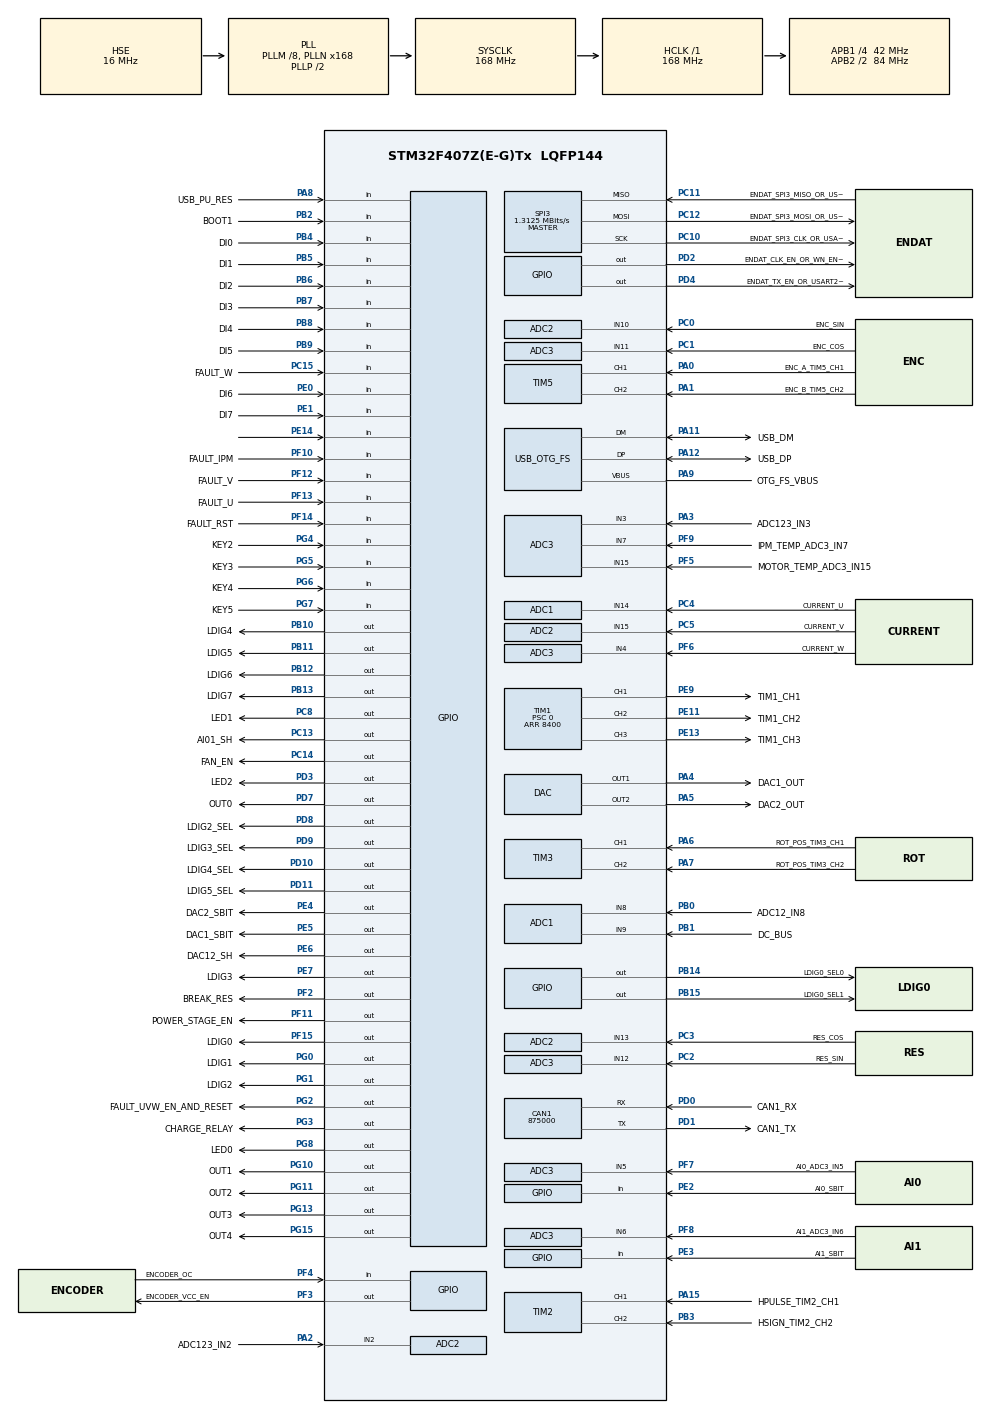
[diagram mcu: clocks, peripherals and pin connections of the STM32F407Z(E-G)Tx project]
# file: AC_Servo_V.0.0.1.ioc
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ADC1.Channel-0\#ChannelRegularConversion=ADC_CHANNEL_8
ADC1.Channel-1\#ChannelInjectedConversion=ADC_CHANNEL_14
ADC1.Channel-2\#ChannelInjectedConversion=ADC_CHANNEL_8
ADC1.Channel-3\#ChannelInjectedConversion=ADC_CHANNEL_9
ADC1.ClockPrescaler=ADC_CLOCK_SYNC_PCLK_DIV4
ADC1.DMAAccessMode=ADC_DMAACCESSMODE_1
ADC1.ExternalTrigInjecConv=ADC_EXTERNALTRIGINJECCONV_T1_TRGO
ADC1.InjNumberOfConversion=3
ADC1.InjectedOffset-1\#ChannelInjectedConversion=0
ADC1.InjectedOffset-2\#ChannelInjectedConversion=0
ADC1.InjectedOffset-3\#ChannelInjectedConversion=0
ADC1.InjectedRank-1\#ChannelInjectedConversion=1
ADC1.InjectedRank-2\#ChannelInjectedConversion=2
ADC1.InjectedRank-3\#ChannelInjectedConversion=3
ADC1.Mode=ADC_TRIPLEMODE_REGSIMULT_INJECSIMULT
ADC1.NbrOfConversionFlag=1
ADC1.Rank-0\#ChannelRegularConversion=1
ADC1.SamplingTime-0\#ChannelRegularConversion=ADC_SAMPLETIME_3CYCLES
ADC1.SamplingTime-1\#ChannelInjectedConversion=ADC_SAMPLETIME_3CYCLES
ADC1.SamplingTime-2\#ChannelInjectedConversion=ADC_SAMPLETIME_3CYCLES
ADC1.SamplingTime-3\#ChannelInjectedConversion=ADC_SAMPLETIME_3CYCLES
ADC1.master=1
ADC2.Channel-0\#ChannelRegularConversion=ADC_CHANNEL_2
ADC2.Channel-1\#ChannelInjectedConversion=ADC_CHANNEL_15
ADC2.Channel-2\#ChannelInjectedConversion=ADC_CHANNEL_2
ADC2.Channel-3\#ChannelInjectedConversion=ADC_CHANNEL_10
ADC2.ClockPrescaler=ADC_CLOCK_SYNC_PCLK_DIV4
ADC2.DMAAccessMode=ADC_DMAACCESSMODE_1
ADC2.InjNumberOfConversion=3
ADC2.InjectedOffset-1\#ChannelInjectedConversion=0
ADC2.InjectedOffset-2\#ChannelInjectedConversion=0
ADC2.InjectedOffset-3\#ChannelInjectedConversion=0
ADC2.InjectedRank-1\#ChannelInjectedConversion=1
ADC2.InjectedRank-2\#ChannelInjectedConversion=2
ADC2.InjectedRank-3\#ChannelInjectedConversion=3
ADC2.Mode=ADC_TRIPLEMODE_REGSIMULT_INJECSIMULT
ADC2.NbrOfConversion=1
ADC2.NbrOfConversionFlag=1
ADC2.Rank-0\#ChannelRegularConversion=1
ADC2.SamplingTime-0\#ChannelRegularConversion=ADC_SAMPLETIME_3CYCLES
ADC2.SamplingTime-1\#ChannelInjectedConversion=ADC_SAMPLETIME_3CYCLES
ADC2.SamplingTime-2\#ChannelInjectedConversion=ADC_SAMPLETIME_3CYCLES
ADC2.SamplingTime-3\#ChannelInjectedConversion=ADC_SAMPLETIME_3CYCLES
ADC3.Channel-0\#ChannelRegularConversion=ADC_CHANNEL_5
ADC3.Channel-1\#ChannelInjectedConversion=ADC_CHANNEL_4
ADC3.Channel-2\#ChannelInjectedConversion=ADC_CHANNEL_3
ADC3.Channel-3\#ChannelInjectedConversion=ADC_CHANNEL_11
ADC3.Channel-4\#ChannelRegularConversion=ADC_CHANNEL_6
ADC3.Channel-5\#ChannelRegularConversion=ADC_CHANNEL_7
ADC3.Channel-6\#ChannelRegularConversion=ADC_CHANNEL_15
ADC3.ClockPrescaler=ADC_CLOCK_SYNC_PCLK_DIV4
ADC3.InjNumberOfConversion=3
ADC3.InjectedOffset-1\#ChannelInjectedConversion=0
ADC3.InjectedOffset-2\#ChannelInjectedConversion=0
ADC3.InjectedOffset-3\#ChannelInjectedConversion=0
ADC3.InjectedRank-1\#ChannelInjectedConversion=1
ADC3.InjectedRank-2\#ChannelInjectedConversion=2
ADC3.InjectedRank-3\#ChannelInjectedConversion=3
ADC3.Mode=ADC_TRIPLEMODE_REGSIMULT_INJECSIMULT
ADC3.NbrOfConversion=4
ADC3.NbrOfConversionFlag=1
ADC3.Rank-0\#ChannelRegularConversion=1
ADC3.Rank-4\#ChannelRegularConversion=2
ADC3.Rank-5\#ChannelRegularConversion=3
ADC3.Rank-6\#ChannelRegularConversion=4
ADC3.SamplingTime-0\#ChannelRegularConversion=ADC_SAMPLETIME_3CYCLES
ADC3.SamplingTime-1\#ChannelInjectedConversion=ADC_SAMPLETIME_3CYCLES
ADC3.SamplingTime-2\#ChannelInjectedConversion=ADC_SAMPLETIME_3CYCLES
ADC3.SamplingTime-3\#ChannelInjectedConversion=ADC_SAMPLETIME_3CYCLES
ADC3.SamplingTime-4\#ChannelRegularConversion=ADC_SAMPLETIME_3CYCLES
ADC3.SamplingTime-5\#ChannelRegularConversion=ADC_SAMPLETIME_3CYCLES
ADC3.SamplingTime-6\#ChannelRegularConversion=ADC_SAMPLETIME_3CYCLES
CAN1.BS1=CAN_BS1_1TQ
CAN1.BS2=CAN_BS2_1TQ
CAN1.CalculateBaudRate=875000
CAN1.CalculateTimeBit=1142
CAN1.CalculateTimeQuantum=380.95238095238096
Dma.ADC3.0.Direction=DMA_PERIPH_TO_MEMORY
Dma.ADC3.0.FIFOMode=DMA_FIFOMODE_DISABLE
Dma.ADC3.0.Instance=DMA2_Stream1
Dma.ADC3.0.MemDataAlignment=DMA_MDATAALIGN_HALFWORD
Dma.ADC3.0.MemInc=DMA_MINC_ENABLE
Dma.ADC3.0.Mode=DMA_CIRCULAR
Dma.ADC3.0.PeriphDataAlignment=DMA_PDATAALIGN_HALFWORD
Dma.ADC3.0.PeriphInc=DMA_PINC_DISABLE
Dma.ADC3.0.Priority=DMA_PRIORITY_LOW
Dma.Request0=ADC3
Mcu.Family=STM32F4
Mcu.Name=STM32F407Z(E-G)Tx
Mcu.Package=LQFP144
NVIC.ADC_IRQn=true\:0\:0\:false\:false\:true\:true\:false\:true
NVIC.DMA2_Stream1_IRQn=true\:0\:0\:false\:false\:true\:false\:false\:true
NVIC.OTG_FS_IRQn=true\:0\:0\:false\:false\:true\:false\:true\:true
NVIC.PriorityGroup=NVIC_PRIORITYGROUP_4
NVIC.TIM1_BRK_TIM9_IRQn=true\:0\:0\:false\:false\:true\:true\:false\:true
PA0-WKUP.GPIO_Label=ENC_A_TIM5_CH1
PA0-WKUP.Signal=S_TIM5_CH1
PA1.GPIO_Label=ENC_B_TIM5_CH2
PA1.Signal=S_TIM5_CH2
PA10.GPIO_Label=USB_ID
PA10.Signal=USB_OTG_FS_ID
PA11.GPIO_Label=USB_DM
PA11.Mode=Device_Only
PA11.Signal=USB_OTG_FS_DM
PA12.GPIO_Label=USB_DP
PA12.Mode=Device_Only
PA12.Signal=USB_OTG_FS_DP
PA13.GPIO_Label=SWDIO
PA13.Signal=SYS_JTMS-SWDIO
PA14.GPIO_Label=SWCLK
PA14.Signal=SYS_JTCK-SWCLK
PA15.GPIO_Label=HPULSE_TIM2_CH1
PA15.Signal=S_TIM2_CH1_ETR
PA2.GPIO_Label=ADC123_IN2
PA2.Signal=ADCx_IN2
PA3.GPIO_Label=ADC123_IN3
PA3.Signal=ADCx_IN3
PA4.GPIO_Label=DAC1_OUT
PA4.Signal=COMP_DAC1_group
PA5.GPIO_Label=DAC2_OUT
PA5.Signal=COMP_DAC2_group
PA6.GPIO_Label=ROT_POS_TIM3_CH1
PA6.Signal=S_TIM3_CH1
PA7.GPIO_Label=ROT_POS_TIM3_CH2
PA7.Signal=S_TIM3_CH2
PA8.GPIO_Label=USB_PU_RES
PA8.Signal=GPIO_Input
PA9.GPIO_Label=OTG_FS_VBUS
PA9.Mode=Activate_VBUS
PA9.Signal=USB_OTG_FS_VBUS
PB0.GPIO_Label=ADC12_IN8
PB0.Signal=ADCx_IN8
PB1.GPIO_Label=DC_BUS
PB1.Signal=ADCx_IN9
PB10.GPIO_Label=LDIG4
PB10.Signal=GPIO_Output
PB11.GPIO_Label=LDIG5
PB11.Signal=GPIO_Output
PB12.GPIO_Label=LDIG6
PB12.GPIO_Speed=GPIO_SPEED_FREQ_LOW
PB12.Signal=GPIO_Output
PB13.GPIO_Label=LDIG7
PB13.Signal=GPIO_Output
PB14.GPIO_Label=LDIG0_SEL0
PB14.Signal=GPIO_Output
PB15.GPIO_Label=LDIG0_SEL1
PB15.Signal=GPIO_Output
PB2.GPIO_Label=BOOT1
PB2.Signal=GPIO_Input
PB3.GPIO_Label=HSIGN_TIM2_CH2
PB3.Signal=S_TIM2_CH2
PB4.GPIO_Label=DI0
PB4.Signal=GPIO_Input
PB5.GPIO_Label=DI1
PB5.Signal=GPIO_Input
PB6.GPIO_Label=DI2
PB6.Signal=GPIO_Input
PB7.GPIO_Label=DI3
PB7.Signal=GPIO_Input
PB8.GPIO_Label=DI4
PB8.Signal=GPIO_Input
PB9.GPIO_Label=DI5
PB9.Signal=GPIO_Input
PC0.GPIO_Label=ENC_SIN
PC0.Signal=ADCx_IN10
PC1.GPIO_Label=ENC_COS
PC1.Signal=ADCx_IN11
PC10.GPIO_Label=ENDAT_SPI3_CLK_OR_USART3_TX
PC10.Mode=Full_Duplex_Master
PC10.Signal=SPI3_SCK
PC11.GPIO_Label=ENDAT_SPI3_MISO_OR_USART3_RX
PC11.GPIO_PuPd=GPIO_NOPULL
PC11.Mode=Full_Duplex_Master
PC11.Signal=SPI3_MISO
PC12.GPIO_Label=ENDAT_SPI3_MOSI_OR_USART3_CK
PC12.GPIO_PuPd=GPIO_NOPULL
PC12.Mode=Full_Duplex_Master
PC12.Signal=SPI3_MOSI
PC13-ANTI_TAMP.GPIO_Label=AI01_SH
PC13-ANTI_TAMP.Signal=GPIO_Output
PC14-OSC32_IN.GPIO_Label=FAN_EN
PC14-OSC32_IN.Signal=GPIO_Output
PC15-OSC32_OUT.GPIO_Label=FAULT_W
PC15-OSC32_OUT.Signal=GPIO_Input
PC2.GPIO_Label=RES_SIN
PC2.Signal=ADCx_IN12
PC3.GPIO_Label=RES_COS
PC3.Signal=ADCx_IN13
PC4.GPIO_Label=CURRENT_U
PC4.Signal=ADCx_IN14
PC5.GPIO_Label=CURRENT_V
PC5.Signal=ADCx_IN15
PC6.GPIO_Label=PULSE_TIM8_CH1
PC6.Signal=S_TIM8_CH1
PC7.GPIO_Label=SIGN_TIM8_CH2
PC7.Signal=S_TIM8_CH2
PC8.GPIO_Label=LED1
PC8.Signal=GPIO_Output
PC9.GPIO_Label=ENC_Z
PC9.Signal=S_TIM3_CH4
PD0.GPIO_Label=CAN1_RX
PD0.Mode=CAN_Activate
PD0.Signal=CAN1_RX
PD1.GPIO_Label=CAN1_TX
PD1.Mode=CAN_Activate
PD1.Signal=CAN1_TX
PD10.GPIO_Label=LDIG4_SEL
PD10.Signal=GPIO_Output
PD11.GPIO_Label=LDIG5_SEL
PD11.Signal=GPIO_Output
PD12.GPIO_Label=TIM4_CH1
PD12.Signal=S_TIM4_CH1
PD13.GPIO_Label=ENC_U
PD13.Signal=S_TIM4_CH2
PD14.GPIO_Label=ENC_V
PD14.Signal=S_TIM4_CH3
PD15.GPIO_Label=ENC_W
PD15.Signal=S_TIM4_CH4
PD2.GPIO_Label=ENDAT_CLK_EN_OR_WN_ENABLE
PD2.Signal=GPIO_Output
PD3.GPIO_Label=LED2
PD3.Signal=GPIO_Output
PD4.GPIO_Label=ENDAT_TX_EN_OR_USART2_RTS
PD4.Signal=GPIO_Output
PD5.GPIO_Label=USART2_TX
PD5.Signal=USART2_TX
PD6.GPIO_Label=USART2_RX
PD6.Signal=USART2_RX
PD7.GPIO_Label=OUT0
PD7.Signal=GPIO_Output
PD8.GPIO_Label=LDIG2_SEL
PD8.Signal=GPIO_Output
PD9.GPIO_Label=LDIG3_SEL
PD9.Signal=GPIO_Output
PE0.GPIO_Label=DI6
PE0.Signal=GPIO_Input
PE1.GPIO_Label=DI7
PE1.Signal=GPIO_Input
PE10.GPIO_Label=TIM1_CH2N
PE10.Signal=TIM1_CH2N
PE11.GPIO_Label=TIM1_CH2
PE11.Signal=S_TIM1_CH2
PE12.GPIO_Label=TIM1_CH3N
PE12.Signal=TIM1_CH3N
PE13.GPIO_Label=TIM1_CH3
PE13.Signal=S_TIM1_CH3
PE14.Signal=GPIO_Input
PE15.GPIO_Label=FAULT_PWM_DISABLE_TIM1_BKIN
PE15.Signal=TIM1_BKIN
PE2.GPIO_Label=AI0_SBIT
PE2.Signal=GPIO_Input
PE3.GPIO_Label=AI1_SBIT
PE3.Signal=GPIO_Input
PE4.GPIO_Label=DAC2_SBIT
PE4.Signal=GPIO_Output
PE5.GPIO_Label=DAC1_SBIT
PE5.Signal=GPIO_Output
PE6.GPIO_Label=DAC12_SH
PE6.Signal=GPIO_Output
PE7.GPIO_Label=LDIG3
PE7.Signal=GPIO_Output
PE8.GPIO_Label=TIM1_CH1N
PE8.Signal=TIM1_CH1N
PE9.GPIO_Label=TIM1_CH1
PE9.Signal=S_TIM1_CH1
PF0.GPIO_Label=I2C2_SDA
PF0.Signal=I2C2_SDA
PF1.GPIO_Label=I2C2_SCL
PF1.Signal=I2C2_SCL
PF10.GPIO_Label=FAULT_IPM
PF10.Signal=GPIO_Input
PF11.GPIO_Label=POWER_STAGE_EN
PF11.Signal=GPIO_Output
PF12.GPIO_Label=FAULT_V
PF12.Signal=GPIO_Input
PF13.GPIO_Label=FAULT_U
PF13.Signal=GPIO_Input
PF14.GPIO_Label=FAULT_RST
PF14.Signal=GPIO_Input
PF15.GPIO_Label=LDIG0
PF15.Signal=GPIO_Output
PF2.GPIO_Label=BREAK_RES
PF2.Signal=GPIO_Output
PF3.GPIO_Label=ENCODER_VCC_EN
PF3.GPIO_ModeDefaultOutputPP=GPIO_MODE_OUTPUT_OD
PF3.PinState=GPIO_PIN_SET
PF3.Signal=GPIO_Output
PF4.GPIO_Label=ENCODER_OC
PF4.Signal=GPIO_Input
PF5.GPIO_Label=MOTOR_TEMP_ADC3_IN15
PF5.Mode=IN15
PF5.Signal=ADC3_IN15
PF6.GPIO_Label=CURRENT_W
PF6.Mode=IN4
PF6.Signal=ADC3_IN4
PF7.GPIO_Label=AI0_ADC3_IN5
PF7.Mode=IN5
PF7.Signal=ADC3_IN5
PF8.GPIO_Label=AI1_ADC3_IN6
PF8.Mode=IN6
PF8.Signal=ADC3_IN6
PF9.GPIO_Label=IPM_TEMP_ADC3_IN7
PF9.Mode=IN7
PF9.Signal=ADC3_IN7
PG0.GPIO_Label=LDIG1
PG0.Signal=GPIO_Output
PG1.GPIO_Label=LDIG2
PG1.Signal=GPIO_Output
PG10.GPIO_Label=OUT1
PG10.Signal=GPIO_Output
PG11.GPIO_Label=OUT2
PG11.Signal=GPIO_Output
PG12.GPIO_Label=RS485_DE_USART6_RTS
PG12.Signal=USART6_RTS
PG13.GPIO_Label=OUT3
PG13.Signal=GPIO_Output
PG14.GPIO_Label=RS485_TX_USART6_TX
PG14.Signal=USART6_TX
PG15.GPIO_Label=OUT4
PG15.Signal=GPIO_Output
PG2.GPIO_Label=FAULT_UVW_EN_AND_RESET
PG2.Signal=GPIO_Output
PG3.GPIO_Label=CHARGE_RELAY
PG3.Signal=GPIO_Output
PG4.GPIO_Label=KEY2
PG4.Signal=GPIO_Input
PG5.GPIO_Label=KEY3
PG5.Signal=GPIO_Input
PG6.GPIO_Label=KEY4
PG6.Signal=GPIO_Input
PG7.GPIO_Label=KEY5
PG7.Signal=GPIO_Input
PG8.GPIO_Label=LED0
PG8.Signal=GPIO_Output
PG9.GPIO_Label=RS485_RX_USART6_RX
PG9.Signal=USART6_RX
PH0-OSC_IN.Mode=HSE-External-Oscillator
PH0-OSC_IN.Signal=RCC_OSC_IN
PH1-OSC_OUT.Mode=HSE-External-Oscillator
PH1-OSC_OUT.Signal=RCC_OSC_OUT
ProjectManager.HeapSize=0x200
ProjectManager.StackSize=0x400
ProjectManager.TargetToolchain=STM32CubeIDE
RCC.48MHZClocksFreq_Value=48000000
RCC.AHBFreq_Value=168000000
RCC.APB1CLKDivider=RCC_HCLK_DIV4
RCC.APB1Freq_Value=42000000
RCC.APB1TimFreq_Value=84000000
RCC.APB2CLKDivider=RCC_HCLK_DIV2
RCC.APB2Freq_Value=84000000
RCC.APB2TimFreq_Value=168000000
RCC.CortexFreq_Value=168000000
RCC.HCLKFreq_Value=168000000
RCC.HSE_VALUE=16000000
RCC.HSI_VALUE=16000000
RCC.LSE_VALUE=32768
RCC.PLLM=8
RCC.PLLN=168
RCC.PLLQ=7
RCC.SYSCLKFreq_VALUE=168000000
RCC.SYSCLKSource=RCC_SYSCLKSOURCE_PLLCLK
RCC.VCOOutputFreq_Value=336000000
SH.ADCx_IN10.0=ADC2_IN10,IN10
SH.ADCx_IN11.0=ADC3_IN11,IN11
SH.ADCx_IN12.0=ADC3_IN12,IN12
SH.ADCx_IN13.0=ADC2_IN13,IN13
SH.ADCx_IN14.0=ADC1_IN14,IN14
SH.ADCx_IN15.0=ADC2_IN15,IN15
SH.ADCx_IN2.0=ADC2_IN2,IN2
SH.ADCx_IN3.0=ADC3_IN3,IN3
SH.ADCx_IN8.0=ADC1_IN8,IN8
SH.ADCx_IN9.0=ADC1_IN9,IN9
SH.COMP_DAC1_group.0=DAC_OUT1,DAC_OUT1
SH.COMP_DAC2_group.0=DAC_OUT2,DAC_OUT2
SH.S_TIM1_CH1.0=TIM1_CH1,PWM Generation1 CH1
SH.S_TIM1_CH2.0=TIM1_CH2,PWM Generation2 CH2
SH.S_TIM1_CH3.0=TIM1_CH3,PWM Generation3 CH3
SH.S_TIM2_CH1_ETR.0=TIM2_CH1,Encoder_Interface
SH.S_TIM2_CH2.0=TIM2_CH2,Encoder_Interface
SH.S_TIM3_CH1.0=TIM3_CH1,Encoder_Interface
SH.S_TIM3_CH2.0=TIM3_CH2,Encoder_Interface
SH.S_TIM3_CH4.0=TIM3_CH4
SH.S_TIM4_CH1.0=TIM4_CH1
SH.S_TIM4_CH2.0=TIM4_CH2
SH.S_TIM4_CH3.0=TIM4_CH3
SH.S_TIM4_CH4.0=TIM4_CH4
SH.S_TIM5_CH1.0=TIM5_CH1,Encoder_Interface
SH.S_TIM5_CH2.0=TIM5_CH2,Encoder_Interface
SH.S_TIM8_CH1.0=TIM8_CH1
SH.S_TIM8_CH2.0=TIM8_CH2
SPI3.BaudRatePrescaler=SPI_BAUDRATEPRESCALER_32
SPI3.CLKPolarity=SPI_POLARITY_HIGH
SPI3.CalculateBaudRate=1.3125 MBits/s
SPI3.Direction=SPI_DIRECTION_2LINES
SPI3.FirstBit=SPI_FIRSTBIT_LSB
SPI3.Mode=SPI_MODE_MASTER
SPI3.VirtualType=VM_MASTER
TIM1.AutoReloadPreload=TIM_AUTORELOAD_PRELOAD_ENABLE
TIM1.AutomaticOutput=TIM_AUTOMATICOUTPUT_DISABLE
TIM1.BreakPolarity=TIM_BREAKPOLARITY_LOW
TIM1.BreakState=TIM_BREAK_ENABLE
TIM1.Channel-PWM\ Generation1\ CH1=TIM_CHANNEL_1
TIM1.Channel-PWM\ Generation2\ CH2=TIM_CHANNEL_2
TIM1.Channel-PWM\ Generation3\ CH3=TIM_CHANNEL_3
TIM1.Channel-PWM\ Generation4\ No\ Output=TIM_CHANNEL_4
TIM1.CounterMode=TIM_COUNTERMODE_CENTERALIGNED1
TIM1.OCMode_PWM-PWM\ Generation1\ CH1=TIM_OCMODE_PWM1
TIM1.OCMode_PWM-PWM\ Generation2\ CH2=TIM_OCMODE_PWM1
TIM1.OCMode_PWM-PWM\ Generation3\ CH3=TIM_OCMODE_PWM1
TIM1.OffStateIDLEMode=TIM_OSSI_ENABLE
TIM1.OffStateRunMode=TIM_OSSR_ENABLE
TIM1.Period=8400
TIM1.Prescaler=0
TIM1.Pulse-PWM\ Generation1\ CH1=4200
TIM1.Pulse-PWM\ Generation2\ CH2=4200
TIM1.Pulse-PWM\ Generation3\ CH3=4200
TIM1.Pulse-PWM\ Generation4\ No\ Output=100
TIM1.RepetitionCounter=1
TIM1.TIM_MasterOutputTrigger=TIM_TRGO_UPDATE
TIM2.IC1Filter=15
TIM2.IC2Filter=15
TIM3.IC1Filter=15
TIM3.IC2Filter=15
USB_DEVICE.CLASS_NAME_FS=CDC
USB_DEVICE.VirtualMode-CDC_FS=Cdc
USB_DEVICE.VirtualModeFS=Cdc_FS
USB_OTG_FS.VirtualMode=Device_Only
VP_TIM1_VS_ClockSourceINT.Mode=Internal
VP_TIM1_VS_no_output4.Mode=PWM Generation4 No Output
VP_USB_DEVICE_VS_USB_DEVICE_CDC_FS.Mode=CDC_FS
board=custom

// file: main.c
/* USER CODE BEGIN Header */
/**
  ******************************************************************************
  * @file           : main.c
  * @brief          : Main program body
  ******************************************************************************
  * @attention
  *
  * <h2><center>&copy; Copyright (c) 2019 STMicroelectronics.
  * All rights reserved.</center></h2>
  *
  * This software component is licensed by ST under BSD 3-Clause license,
  * the "License"; You may not use this file except in compliance with the
  * License. You may obtain a copy of the License at:
  *                        opensource.org/licenses/BSD-3-Clause
  *
  ******************************************************************************
  */
/* USER CODE END Header */
#include "main.h"

/* USER CODE BEGIN Includes */
#include <math.h>
#include "endat.h"
#include "foc.h"
/* USER CODE END Includes */

ADC_HandleTypeDef hadc1;
ADC_HandleTypeDef hadc2;
ADC_HandleTypeDef hadc3;
DMA_HandleTypeDef hdma_adc3;

CAN_HandleTypeDef hcan1;

DAC_HandleTypeDef hdac;

SPI_HandleTypeDef hspi3;

TIM_HandleTypeDef htim1;
TIM_HandleTypeDef htim2;
TIM_HandleTypeDef htim3;
TIM_HandleTypeDef htim5;

PCD_HandleTypeDef hpcd_USB_OTG_FS;

/* USER CODE BEGIN PV */
volatile uint8_t encoder_pwr_en = 1;
volatile uint16_t arrADC[15];
volatile float s, c;

volatile int16_t arrADC1[15];
volatile uint16_t arrOffset[15];
volatile uint32_t arrOffsetSum[15];

volatile float angle, delta = 0.0f;
volatile float min = 0, max = 0, angle;

volatile uint16_t tim3;
volatile uint32_t tim5, upos;
volatile int32_t pos;

endat_data_t st_EnDat;

uint8_t main_state = 0;

uint8_t adc_is_ready = 0;
uint32_t sin_sum, cos_sum, average_cnt;

MC_FOC stFoc;
/* USER CODE END PV */

void SystemClock_Config(void);
static void MX_GPIO_Init(void);
static void MX_DMA_Init(void);
static void MX_TIM1_Init(void);
static void MX_TIM2_Init(void);
static void MX_TIM3_Init(void);
static void MX_TIM5_Init(void);
static void MX_ADC1_Init(void);
static void MX_ADC2_Init(void);
static void MX_ADC3_Init(void);
static void MX_DAC_Init(void);
static void MX_SPI3_Init(void);
static void MX_CAN1_Init(void);
static void MX_USB_OTG_FS_PCD_Init(void);

int main(void)
{

  /* MCU Configuration--------------------------------------------------------*/

  /* Reset of all peripherals, Initializes the Flash interface and the Systick. */
  HAL_Init();

  /* Configure the system clock */
  SystemClock_Config();

  /* USER CODE BEGIN SysInit */
  focInit( &stFoc );
  createSinCosTable();
  /* USER CODE END SysInit */

  /* Initialize all configured peripherals */
  MX_GPIO_Init();
  MX_DMA_Init();
  MX_TIM1_Init();
  MX_TIM2_Init();
  MX_TIM3_Init();
  MX_TIM5_Init();
  MX_ADC1_Init();
  MX_ADC2_Init();
  MX_ADC3_Init();
  MX_DAC_Init();
  MX_SPI3_Init();
  MX_CAN1_Init();
  MX_USB_OTG_FS_PCD_Init();
  /* USER CODE BEGIN 2 */
  HAL_TIM_PWM_Start( &htim1, TIM_CHANNEL_1 );
  HAL_TIM_PWM_Start( &htim1, TIM_CHANNEL_2 );
  HAL_TIM_PWM_Start( &htim1, TIM_CHANNEL_3 );
  HAL_TIM_PWM_Start( &htim1, TIM_CHANNEL_4 );
  /* USER CODE END 2 */

  /* Infinite loop */
  /* USER CODE BEGIN WHILE */
//en_dat_inti();
  HAL_GPIO_WritePin( GPIOD, ENDAT_CLK_EN_OR_WN_ENABLE_Pin, GPIO_PIN_SET );
  while (1)
  {
	  switch( main_state )
	  {
	  case 0:
		  stFoc.enable = 0;

		  encoder_pwr_en = 0;;
		  sin_sum = 0;
		  cos_sum = 0;
		  average_cnt = 0;
		  main_state = 1;
		  break;

	  case 1:
		  if( average_cnt < 1000 )
		  {
			  average_cnt++;
		  } else {
			  average_cnt = 0;
			  main_state = 2;
		  }
		  break;

	  case 2:
		  if( average_cnt < 8 )
		  {
			  if( adc_is_ready )
			  {
				  average_cnt++;

				  for( int i = 0; i < 15; i++ )
				  {
					  arrOffsetSum[i] += arrADC[i];
				  }

				  adc_is_ready = 0;
			  }
		  } else {
			  for( int i = 0; i < 15; i++ )
			  {
				  arrOffset[i] = arrOffsetSum[i] / 8;
			  }

			  stFoc.current_a_offset = arrOffset[0];
			  stFoc.current_b_offset = arrOffset[4];
			  stFoc.current_c_offset = arrOffset[8];
			  main_state = 3;
		  }
		  break;

	  case 3:
		  encoder_pwr_en = 1;
		  main_state = 4;
		  break;

	  case 4:
		  stFoc.enable = 1;

		  for( int i = 0; i < 15; i++ )
		  {
			  arrADC1[i] = arrADC[i] - arrOffset[i];
		  }

		  if( arrADC1[10] )
		  {
			  int32_t temp;
			  float at;

			  s = arrADC1[6];
			  c = arrADC1[10];
			  at = 4095.0f - ( 4095.0f * (( 1.5232 + atan( s / c ) ) / 3.09324f) );

			  //temp = ( ( tim5 % 1023 ) << 12) + ( (uint16_t)at & 0x0fff );
			  temp = ( tim3<<12) + ( (uint16_t)at & 0x0fff );
			  angle= (float)temp / 4096.0f;
			  pos = temp;
		  }

		  //GPIOD->BSRR |= LED2_Pin;
		  endat_func( 0.0f, &st_EnDat );
		  //GPIOD->BSRR |= LED2_Pin<<16;
		  break;
	  }

	  if( encoder_pwr_en )
	  {
		  HAL_GPIO_WritePin(ENCODER_VCC_EN_GPIO_Port, ENCODER_VCC_EN_Pin, GPIO_PIN_RESET);
	  } else {
		  HAL_GPIO_WritePin(ENCODER_VCC_EN_GPIO_Port, ENCODER_VCC_EN_Pin, GPIO_PIN_SET);
	  }

	  HAL_DAC_SetValue( &hdac, DAC_CHANNEL_1, DAC_ALIGN_12B_R, angle+1500 );
	  HAL_DAC_SetValue( &hdac, DAC_CHANNEL_2, DAC_ALIGN_12B_R, 0 );

    /* USER CODE END WHILE */

    /* USER CODE BEGIN 3 */
	  /*uint8_t txEnData[10];

	  txEnData[0] = 0xAA;
	  txEnData[1] = 0x55;

	  HAL_GPIO_WritePin( GPIOD, ENDAT_TX_EN_OR_USART2_RTS_Pin, GPIO_PIN_SET );
	  HAL_SPI_Transmit( &hspi3, txEnData, 10, 1 );
	  HAL_GPIO_WritePin( GPIOD, ENDAT_TX_EN_OR_USART2_RTS_Pin, GPIO_PIN_RESET );*/
  }
  /* USER CODE END 3 */
}

void SystemClock_Config(void)
{
  RCC_OscInitTypeDef RCC_OscInitStruct = {0};
  RCC_ClkInitTypeDef RCC_ClkInitStruct = {0};

  /** Configure the main internal regulator output voltage
  */
  __HAL_RCC_PWR_CLK_ENABLE();
  __HAL_PWR_VOLTAGESCALING_CONFIG(PWR_REGULATOR_VOLTAGE_SCALE1);
  /** Initializes the RCC Oscillators according to the specified parameters
  * in the RCC_OscInitTypeDef structure.
  */
  RCC_OscInitStruct.OscillatorType = RCC_OSCILLATORTYPE_HSE;
  RCC_OscInitStruct.HSEState = RCC_HSE_ON;
  RCC_OscInitStruct.PLL.PLLState = RCC_PLL_ON;
  RCC_OscInitStruct.PLL.PLLSource = RCC_PLLSOURCE_HSE;
  RCC_OscInitStruct.PLL.PLLM = 8;
  RCC_OscInitStruct.PLL.PLLN = 168;
  RCC_OscInitStruct.PLL.PLLP = RCC_PLLP_DIV2;
  RCC_OscInitStruct.PLL.PLLQ = 7;
  if (HAL_RCC_OscConfig(&RCC_OscInitStruct) != HAL_OK)
  {
    Error_Handler();
  }
  /** Initializes the CPU, AHB and APB buses clocks
  */
  RCC_ClkInitStruct.ClockType = RCC_CLOCKTYPE_HCLK|RCC_CLOCKTYPE_SYSCLK
                              |RCC_CLOCKTYPE_PCLK1|RCC_CLOCKTYPE_PCLK2;
  RCC_ClkInitStruct.SYSCLKSource = RCC_SYSCLKSOURCE_PLLCLK;
  RCC_ClkInitStruct.AHBCLKDivider = RCC_SYSCLK_DIV1;
  RCC_ClkInitStruct.APB1CLKDivider = RCC_HCLK_DIV4;
  RCC_ClkInitStruct.APB2CLKDivider = RCC_HCLK_DIV2;

  if (HAL_RCC_ClockConfig(&RCC_ClkInitStruct, FLASH_LATENCY_5) != HAL_OK)
  {
    Error_Handler();
  }
}

static void MX_ADC1_Init(void)
{

  ADC_MultiModeTypeDef multimode = {0};
  ADC_ChannelConfTypeDef sConfig = {0};
  ADC_InjectionConfTypeDef sConfigInjected = {0};

  /** Configure the global features of the ADC (Clock, Resolution, Data Alignment and number of conversion)
  */
  hadc1.Instance = ADC1;
  hadc1.Init.ClockPrescaler = ADC_CLOCK_SYNC_PCLK_DIV4;
  hadc1.Init.Resolution = ADC_RESOLUTION_12B;
  hadc1.Init.ScanConvMode = ENABLE;
  hadc1.Init.ContinuousConvMode = DISABLE;
  hadc1.Init.DiscontinuousConvMode = DISABLE;
  hadc1.Init.ExternalTrigConvEdge = ADC_EXTERNALTRIGCONVEDGE_NONE;
  hadc1.Init.ExternalTrigConv = ADC_SOFTWARE_START;
  hadc1.Init.DataAlign = ADC_DATAALIGN_RIGHT;
  hadc1.Init.NbrOfConversion = 1;
  hadc1.Init.DMAContinuousRequests = DISABLE;
  hadc1.Init.EOCSelection = ADC_EOC_SINGLE_CONV;
  if (HAL_ADC_Init(&hadc1) != HAL_OK)
  {
    Error_Handler();
  }
  /** Configure the ADC multi-mode
  */
  multimode.Mode = ADC_TRIPLEMODE_REGSIMULT_INJECSIMULT;
  multimode.DMAAccessMode = ADC_DMAACCESSMODE_1;
  multimode.TwoSamplingDelay = ADC_TWOSAMPLINGDELAY_5CYCLES;
  if (HAL_ADCEx_MultiModeConfigChannel(&hadc1, &multimode) != HAL_OK)
  {
    Error_Handler();
  }
  /** Configure for the selected ADC regular channel its corresponding rank in the sequencer and its sample time.
  */
  sConfig.Channel = ADC_CHANNEL_8;
  sConfig.Rank = 1;
  sConfig.SamplingTime = ADC_SAMPLETIME_3CYCLES;
  if (HAL_ADC_ConfigChannel(&hadc1, &sConfig) != HAL_OK)
  {
    Error_Handler();
  }
  /** Configures for the selected ADC injected channel its corresponding rank in the sequencer and its sample time
  */
  sConfigInjected.InjectedChannel = ADC_CHANNEL_14;
  sConfigInjected.InjectedRank = 1;
  sConfigInjected.InjectedNbrOfConversion = 3;
  sConfigInjected.InjectedSamplingTime = ADC_SAMPLETIME_3CYCLES;
  sConfigInjected.ExternalTrigInjecConvEdge = ADC_EXTERNALTRIGINJECCONVEDGE_RISING;
  sConfigInjected.ExternalTrigInjecConv = ADC_EXTERNALTRIGINJECCONV_T1_TRGO;
  sConfigInjected.AutoInjectedConv = DISABLE;
  sConfigInjected.InjectedDiscontinuousConvMode = DISABLE;
  sConfigInjected.InjectedOffset = 0;
  if (HAL_ADCEx_InjectedConfigChannel(&hadc1, &sConfigInjected) != HAL_OK)
  {
    Error_Handler();
  }
  /** Configures for the selected ADC injected channel its corresponding rank in the sequencer and its sample time
  */
  sConfigInjected.InjectedChannel = ADC_CHANNEL_8;
  sConfigInjected.InjectedRank = 2;
  if (HAL_ADCEx_InjectedConfigChannel(&hadc1, &sConfigInjected) != HAL_OK)
  {
    Error_Handler();
  }
  /** Configures for the selected ADC injected channel its corresponding rank in the sequencer and its sample time
  */
  sConfigInjected.InjectedChannel = ADC_CHANNEL_9;
  sConfigInjected.InjectedRank = 3;
  if (HAL_ADCEx_InjectedConfigChannel(&hadc1, &sConfigInjected) != HAL_OK)
  {
    Error_Handler();
  }
  /* USER CODE BEGIN ADC1_Init 2 */
  __HAL_ADC_ENABLE_IT( &hadc1, ADC_IT_EOC | ADC_IT_JEOC );
  HAL_ADC_Start( &hadc1 );
  /* USER CODE END ADC1_Init 2 */

}

static void MX_ADC2_Init(void)
{

  ADC_ChannelConfTypeDef sConfig = {0};
  ADC_InjectionConfTypeDef sConfigInjected = {0};

  /** Configure the global features of the ADC (Clock, Resolution, Data Alignment and number of conversion)
  */
  hadc2.Instance = ADC2;
  hadc2.Init.ClockPrescaler = ADC_CLOCK_SYNC_PCLK_DIV4;
  hadc2.Init.Resolution = ADC_RESOLUTION_12B;
  hadc2.Init.ScanConvMode = ENABLE;
  hadc2.Init.ContinuousConvMode = DISABLE;
  hadc2.Init.DiscontinuousConvMode = DISABLE;
  hadc2.Init.DataAlign = ADC_DATAALIGN_RIGHT;
  hadc2.Init.NbrOfConversion = 1;
  hadc2.Init.DMAContinuousRequests = DISABLE;
  hadc2.Init.EOCSelection = ADC_EOC_SINGLE_CONV;
  if (HAL_ADC_Init(&hadc2) != HAL_OK)
  {
    Error_Handler();
  }
  /** Configure for the selected ADC regular channel its corresponding rank in the sequencer and its sample time.
  */
  sConfig.Channel = ADC_CHANNEL_2;
  sConfig.Rank = 1;
  sConfig.SamplingTime = ADC_SAMPLETIME_3CYCLES;
  if (HAL_ADC_ConfigChannel(&hadc2, &sConfig) != HAL_OK)
  {
    Error_Handler();
  }
  /** Configures for the selected ADC injected channel its corresponding rank in the sequencer and its sample time
  */
  sConfigInjected.InjectedChannel = ADC_CHANNEL_15;
  sConfigInjected.InjectedRank = 1;
  sConfigInjected.InjectedNbrOfConversion = 3;
  sConfigInjected.InjectedSamplingTime = ADC_SAMPLETIME_3CYCLES;
  sConfigInjected.AutoInjectedConv = ENABLE;
  sConfigInjected.InjectedDiscontinuousConvMode = DISABLE;
  sConfigInjected.InjectedOffset = 0;
  if (HAL_ADCEx_InjectedConfigChannel(&hadc2, &sConfigInjected) != HAL_OK)
  {
    Error_Handler();
  }
  /** Configures for the selected ADC injected channel its corresponding rank in the sequencer and its sample time
  */
  sConfigInjected.InjectedChannel = ADC_CHANNEL_2;
  sConfigInjected.InjectedRank = 2;
  if (HAL_ADCEx_InjectedConfigChannel(&hadc2, &sConfigInjected) != HAL_OK)
  {
    Error_Handler();
  }
  /** Configures for the selected ADC injected channel its corresponding rank in the sequencer and its sample time
  */
  sConfigInjected.InjectedChannel = ADC_CHANNEL_10;
  sConfigInjected.InjectedRank = 3;
  if (HAL_ADCEx_InjectedConfigChannel(&hadc2, &sConfigInjected) != HAL_OK)
  {
    Error_Handler();
  }
  /* USER CODE BEGIN ADC2_Init 2 */
  __HAL_ADC_ENABLE_IT( &hadc2, ADC_IT_EOC | ADC_IT_JEOC );
  HAL_ADC_Start( &hadc2 );
  /* USER CODE END ADC2_Init 2 */

}

static void MX_ADC3_Init(void)
{

  ADC_ChannelConfTypeDef sConfig = {0};
  ADC_InjectionConfTypeDef sConfigInjected = {0};

  /** Configure the global features of the ADC (Clock, Resolution, Data Alignment and number of conversion)
  */
  hadc3.Instance = ADC3;
  hadc3.Init.ClockPrescaler = ADC_CLOCK_SYNC_PCLK_DIV4;
  hadc3.Init.Resolution = ADC_RESOLUTION_12B;
  hadc3.Init.ScanConvMode = ENABLE;
  hadc3.Init.ContinuousConvMode = DISABLE;
  hadc3.Init.DiscontinuousConvMode = DISABLE;
  hadc3.Init.DataAlign = ADC_DATAALIGN_RIGHT;
  hadc3.Init.NbrOfConversion = 4;
  hadc3.Init.DMAContinuousRequests = DISABLE;
  hadc3.Init.EOCSelection = ADC_EOC_SINGLE_CONV;
  if (HAL_ADC_Init(&hadc3) != HAL_OK)
  {
    Error_Handler();
  }
  /** Configure for the selected ADC regular channel its corresponding rank in the sequencer and its sample time.
  */
  sConfig.Channel = ADC_CHANNEL_5;
  sConfig.Rank = 1;
  sConfig.SamplingTime = ADC_SAMPLETIME_3CYCLES;
  if (HAL_ADC_ConfigChannel(&hadc3, &sConfig) != HAL_OK)
  {
    Error_Handler();
  }
  /** Configure for the selected ADC regular channel its corresponding rank in the sequencer and its sample time.
  */
  sConfig.Channel = ADC_CHANNEL_6;
  sConfig.Rank = 2;
  if (HAL_ADC_ConfigChannel(&hadc3, &sConfig) != HAL_OK)
  {
    Error_Handler();
  }
  /** Configure for the selected ADC regular channel its corresponding rank in the sequencer and its sample time.
  */
  sConfig.Channel = ADC_CHANNEL_7;
  sConfig.Rank = 3;
  if (HAL_ADC_ConfigChannel(&hadc3, &sConfig) != HAL_OK)
  {
    Error_Handler();
  }
  /** Configure for the selected ADC regular channel its corresponding rank in the sequencer and its sample time.
  */
  sConfig.Channel = ADC_CHANNEL_15;
  sConfig.Rank = 4;
  if (HAL_ADC_ConfigChannel(&hadc3, &sConfig) != HAL_OK)
  {
    Error_Handler();
  }
  /** Configures for the selected ADC injected channel its corresponding rank in the sequencer and its sample time
  */
  sConfigInjected.InjectedChannel = ADC_CHANNEL_4;
  sConfigInjected.InjectedRank = 1;
  sConfigInjected.InjectedNbrOfConversion = 3;
  sConfigInjected.InjectedSamplingTime = ADC_SAMPLETIME_3CYCLES;
  sConfigInjected.AutoInjectedConv = ENABLE;
  sConfigInjected.InjectedDiscontinuousConvMode = DISABLE;
  sConfigInjected.InjectedOffset = 0;
  if (HAL_ADCEx_InjectedConfigChannel(&hadc3, &sConfigInjected) != HAL_OK)
  {
    Error_Handler();
  }
  /** Configures for the selected ADC injected channel its corresponding rank in the sequencer and its sample time
  */
  sConfigInjected.InjectedChannel = ADC_CHANNEL_3;
  sConfigInjected.InjectedRank = 2;
  if (HAL_ADCEx_InjectedConfigChannel(&hadc3, &sConfigInjected) != HAL_OK)
  {
    Error_Handler();
  }
  /** Configures for the selected ADC injected channel its corresponding rank in the sequencer and its sample time
  */
  sConfigInjected.InjectedChannel = ADC_CHANNEL_11;
  sConfigInjected.InjectedRank = 3;
  if (HAL_ADCEx_InjectedConfigChannel(&hadc3, &sConfigInjected) != HAL_OK)
  {
    Error_Handler();
  }
  /* USER CODE BEGIN ADC3_Init 2 */
  __HAL_ADC_ENABLE_IT( &hadc3, ADC_IT_EOC | ADC_IT_JEOC );
  HAL_ADC_Start( &hadc3 );
  /* USER CODE END ADC3_Init 2 */

}

static void MX_CAN1_Init(void)
{

  hcan1.Instance = CAN1;
  hcan1.Init.Prescaler = 16;
  hcan1.Init.Mode = CAN_MODE_NORMAL;
  hcan1.Init.SyncJumpWidth = CAN_SJW_1TQ;
  hcan1.Init.TimeSeg1 = CAN_BS1_1TQ;
  hcan1.Init.TimeSeg2 = CAN_BS2_1TQ;
  hcan1.Init.TimeTriggeredMode = DISABLE;
  hcan1.Init.AutoBusOff = DISABLE;
  hcan1.Init.AutoWakeUp = DISABLE;
  hcan1.Init.AutoRetransmission = DISABLE;
  hcan1.Init.ReceiveFifoLocked = DISABLE;
  hcan1.Init.TransmitFifoPriority = DISABLE;
  if (HAL_CAN_Init(&hcan1) != HAL_OK)
  {
    Error_Handler();
  }

}

static void MX_DAC_Init(void)
{

  DAC_ChannelConfTypeDef sConfig = {0};

  /** DAC Initialization
  */
  hdac.Instance = DAC;
  if (HAL_DAC_Init(&hdac) != HAL_OK)
  {
    Error_Handler();
  }
  /** DAC channel OUT1 config
  */
  sConfig.DAC_Trigger = DAC_TRIGGER_NONE;
  sConfig.DAC_OutputBuffer = DAC_OUTPUTBUFFER_ENABLE;
  if (HAL_DAC_ConfigChannel(&hdac, &sConfig, DAC_CHANNEL_1) != HAL_OK)
  {
    Error_Handler();
  }
  /** DAC channel OUT2 config
  */
  if (HAL_DAC_ConfigChannel(&hdac, &sConfig, DAC_CHANNEL_2) != HAL_OK)
  {
    Error_Handler();
  }
  /* USER CODE BEGIN DAC_Init 2 */
  HAL_DAC_Start( &hdac, DAC_CHANNEL_1 );
  HAL_DAC_Start( &hdac, DAC_CHANNEL_2 );
  /* USER CODE END DAC_Init 2 */

}

static void MX_SPI3_Init(void)
{

  /* SPI3 parameter configuration*/
  hspi3.Instance = SPI3;
  hspi3.Init.Mode = SPI_MODE_MASTER;
  hspi3.Init.Direction = SPI_DIRECTION_2LINES;
  hspi3.Init.DataSize = SPI_DATASIZE_8BIT;
  hspi3.Init.CLKPolarity = SPI_POLARITY_HIGH;
  hspi3.Init.CLKPhase = SPI_PHASE_1EDGE;
  hspi3.Init.NSS = SPI_NSS_SOFT;
  hspi3.Init.BaudRatePrescaler = SPI_BAUDRATEPRESCALER_32;
  hspi3.Init.FirstBit = SPI_FIRSTBIT_LSB;
  hspi3.Init.TIMode = SPI_TIMODE_DISABLE;
  hspi3.Init.CRCCalculation = SPI_CRCCALCULATION_DISABLE;
  hspi3.Init.CRCPolynomial = 10;
  if (HAL_SPI_Init(&hspi3) != HAL_OK)
  {
    Error_Handler();
  }

}

static void MX_TIM1_Init(void)
{

  TIM_ClockConfigTypeDef sClockSourceConfig = {0};
  TIM_MasterConfigTypeDef sMasterConfig = {0};
  TIM_OC_InitTypeDef sConfigOC = {0};
  TIM_BreakDeadTimeConfigTypeDef sBreakDeadTimeConfig = {0};

  htim1.Instance = TIM1;
  htim1.Init.Prescaler = 3;
  htim1.Init.CounterMode = TIM_COUNTERMODE_CENTERALIGNED2;
  htim1.Init.Period = 4200;
  htim1.Init.ClockDivision = TIM_CLOCKDIVISION_DIV1;
  htim1.Init.RepetitionCounter = 0;
  htim1.Init.AutoReloadPreload = TIM_AUTORELOAD_PRELOAD_ENABLE;
  if (HAL_TIM_Base_Init(&htim1) != HAL_OK)
  {
    Error_Handler();
  }
  sClockSourceConfig.ClockSource = TIM_CLOCKSOURCE_INTERNAL;
  if (HAL_TIM_ConfigClockSource(&htim1, &sClockSourceConfig) != HAL_OK)
  {
    Error_Handler();
  }
  if (HAL_TIM_OC_Init(&htim1) != HAL_OK)
  {
    Error_Handler();
  }
  sMasterConfig.MasterOutputTrigger = TIM_TRGO_UPDATE;
  sMasterConfig.MasterSlaveMode = TIM_MASTERSLAVEMODE_DISABLE;
  if (HAL_TIMEx_MasterConfigSynchronization(&htim1, &sMasterConfig) != HAL_OK)
  {
    Error_Handler();
  }
  sConfigOC.OCMode = TIM_OCMODE_TIMING;
  sConfigOC.Pulse = 500;
  sConfigOC.OCPolarity = TIM_OCPOLARITY_HIGH;
  sConfigOC.OCNPolarity = TIM_OCNPOLARITY_HIGH;
  sConfigOC.OCFastMode = TIM_OCFAST_DISABLE;
  sConfigOC.OCIdleState = TIM_OCIDLESTATE_RESET;
  sConfigOC.OCNIdleState = TIM_OCNIDLESTATE_RESET;
  if (HAL_TIM_OC_ConfigChannel(&htim1, &sConfigOC, TIM_CHANNEL_1) != HAL_OK)
  {
    Error_Handler();
  }
  if (HAL_TIM_OC_ConfigChannel(&htim1, &sConfigOC, TIM_CHANNEL_2) != HAL_OK)
  {
    Error_Handler();
  }
  if (HAL_TIM_OC_ConfigChannel(&htim1, &sConfigOC, TIM_CHANNEL_3) != HAL_OK)
  {
    Error_Handler();
  }
  sConfigOC.Pulse = 10;
  if (HAL_TIM_OC_ConfigChannel(&htim1, &sConfigOC, TIM_CHANNEL_4) != HAL_OK)
  {
    Error_Handler();
  }
  sBreakDeadTimeConfig.OffStateRunMode = TIM_OSSR_DISABLE;
  sBreakDeadTimeConfig.OffStateIDLEMode = TIM_OSSI_DISABLE;
  sBreakDeadTimeConfig.LockLevel = TIM_LOCKLEVEL_OFF;
  sBreakDeadTimeConfig.DeadTime = 0;
  sBreakDeadTimeConfig.BreakState = TIM_BREAK_DISABLE;
  sBreakDeadTimeConfig.BreakPolarity = TIM_BREAKPOLARITY_LOW;
  sBreakDeadTimeConfig.AutomaticOutput = TIM_AUTOMATICOUTPUT_DISABLE;
  if (HAL_TIMEx_ConfigBreakDeadTime(&htim1, &sBreakDeadTimeConfig) != HAL_OK)
  {
    Error_Handler();
  }
  HAL_TIM_MspPostInit(&htim1);

}

static void MX_TIM2_Init(void)
{

  TIM_Encoder_InitTypeDef sConfig = {0};
  TIM_MasterConfigTypeDef sMasterConfig = {0};

  htim2.Instance = TIM2;
  htim2.Init.Prescaler = 0;
  htim2.Init.CounterMode = TIM_COUNTERMODE_UP;
  htim2.Init.Period = 4294967295;
  htim2.Init.ClockDivision = TIM_CLOCKDIVISION_DIV1;
  htim2.Init.AutoReloadPreload = TIM_AUTORELOAD_PRELOAD_DISABLE;
  sConfig.EncoderMode = TIM_ENCODERMODE_TI1;
  sConfig.IC1Polarity = TIM_ICPOLARITY_RISING;
  sConfig.IC1Selection = TIM_ICSELECTION_DIRECTTI;
  sConfig.IC1Prescaler = TIM_ICPSC_DIV1;
  sConfig.IC1Filter = 15;
  sConfig.IC2Polarity = TIM_ICPOLARITY_RISING;
  sConfig.IC2Selection = TIM_ICSELECTION_DIRECTTI;
  sConfig.IC2Prescaler = TIM_ICPSC_DIV1;
  sConfig.IC2Filter = 15;
  if (HAL_TIM_Encoder_Init(&htim2, &sConfig) != HAL_OK)
  {
    Error_Handler();
  }
  sMasterConfig.MasterOutputTrigger = TIM_TRGO_RESET;
  sMasterConfig.MasterSlaveMode = TIM_MASTERSLAVEMODE_DISABLE;
  if (HAL_TIMEx_MasterConfigSynchronization(&htim2, &sMasterConfig) != HAL_OK)
  {
    Error_Handler();
  }

}

static void MX_TIM3_Init(void)
{

  TIM_Encoder_InitTypeDef sConfig = {0};
  TIM_MasterConfigTypeDef sMasterConfig = {0};

  htim3.Instance = TIM3;
  htim3.Init.Prescaler = 0;
  htim3.Init.CounterMode = TIM_COUNTERMODE_UP;
  htim3.Init.Period = 65535;
  htim3.Init.ClockDivision = TIM_CLOCKDIVISION_DIV1;
  htim3.Init.AutoReloadPreload = TIM_AUTORELOAD_PRELOAD_DISABLE;
  sConfig.EncoderMode = TIM_ENCODERMODE_TI1;
  sConfig.IC1Polarity = TIM_ICPOLARITY_RISING;
  sConfig.IC1Selection = TIM_ICSELECTION_DIRECTTI;
  sConfig.IC1Prescaler = TIM_ICPSC_DIV1;
  sConfig.IC1Filter = 15;
  sConfig.IC2Polarity = TIM_ICPOLARITY_RISING;
  sConfig.IC2Selection = TIM_ICSELECTION_DIRECTTI;
  sConfig.IC2Prescaler = TIM_ICPSC_DIV1;
  sConfig.IC2Filter = 15;
  if (HAL_TIM_Encoder_Init(&htim3, &sConfig) != HAL_OK)
  {
    Error_Handler();
  }
  sMasterConfig.MasterOutputTrigger = TIM_TRGO_RESET;
  sMasterConfig.MasterSlaveMode = TIM_MASTERSLAVEMODE_DISABLE;
  if (HAL_TIMEx_MasterConfigSynchronization(&htim3, &sMasterConfig) != HAL_OK)
  {
    Error_Handler();
  }
  /* USER CODE BEGIN TIM3_Init 2 */
  /*
   * Polzva se Sin-Cos encoder s 512 ppr. Umnojeno po 2: 1024. Stojnostta na APP stava 1023. Obache posledniq "ipmuls"
   * se otchita ot ATAN( SIN / COS ) - ot 0.0001 do 0.9999. Taka che APP stava: 1024 - 1 - 0.999 = 1022;
   */
  htim3.Instance->ARR = 1022;
  htim3.Instance->SMCR &= ~TIM_ENCODERMODE_TI12;
  htim3.Instance->SMCR |= TIM_ENCODERMODE_TI2;
  HAL_TIM_Encoder_Start( &htim3, TIM_CHANNEL_ALL );

  HAL_TIM_Encoder_Start( &htim3, TIM_CHANNEL_ALL );
  /* USER CODE END TIM3_Init 2 */
}

static void MX_TIM5_Init(void)
{

  TIM_Encoder_InitTypeDef sConfig = {0};
  TIM_MasterConfigTypeDef sMasterConfig = {0};

  htim5.Instance = TIM5;
  htim5.Init.Prescaler = 0;
  htim5.Init.CounterMode = TIM_COUNTERMODE_UP;
  htim5.Init.Period = 4294967295;
  htim5.Init.ClockDivision = TIM_CLOCKDIVISION_DIV1;
  htim5.Init.AutoReloadPreload = TIM_AUTORELOAD_PRELOAD_DISABLE;
  sConfig.EncoderMode = TIM_ENCODERMODE_TI1;
  sConfig.IC1Polarity = TIM_ICPOLARITY_RISING;
  sConfig.IC1Selection = TIM_ICSELECTION_DIRECTTI;
  sConfig.IC1Prescaler = TIM_ICPSC_DIV1;
  sConfig.IC1Filter = 0;
  sConfig.IC2Polarity = TIM_ICPOLARITY_RISING;
  sConfig.IC2Selection = TIM_ICSELECTION_DIRECTTI;
  sConfig.IC2Prescaler = TIM_ICPSC_DIV1;
  sConfig.IC2Filter = 0;
  if (HAL_TIM_Encoder_Init(&htim5, &sConfig) != HAL_OK)
  {
    Error_Handler();
  }
  sMasterConfig.MasterOutputTrigger = TIM_TRGO_RESET;
  sMasterConfig.MasterSlaveMode = TIM_MASTERSLAVEMODE_DISABLE;
  if (HAL_TIMEx_MasterConfigSynchronization(&htim5, &sMasterConfig) != HAL_OK)
  {
    Error_Handler();
  }
  /* USER CODE BEGIN TIM5_Init 2 */
  //TIM_ENCODERMODE_TI1 (TIM_SMCR_SMS_0) - Quadrature encoder mode 1, x2 mode, counts up/down on TI1FP1 edge depending on TI2FP2 level.
  //TIM_ENCODERMODE_TI2 (TIM_SMCR_SMS_1) - Quadrature encoder mode 2, x2 mode, counts up/down on TI2FP2 edge depending on TI1FP1 level.
  //TIM_ENCODERMODE_TI12 (TIM_SMCR_SMS_1 | TIM_SMCR_SMS_0) - Quadrature encoder mode 3, x4 mode, counts up/down on both TI1FP1 and TI2FP2 edges depending on the level of the other input.

  htim5.Instance->SMCR &= ~TIM_ENCODERMODE_TI12;
  htim5.Instance->SMCR |= TIM_ENCODERMODE_TI2;
  //htim5.Instance->SMCR |= TIM_ENCODERMODE_TI12; x4

  HAL_TIM_Encoder_Start( &htim5, TIM_CHANNEL_ALL );
  /* USER CODE END TIM5_Init 2 */

}

static void MX_USB_OTG_FS_PCD_Init(void)
{

  hpcd_USB_OTG_FS.Instance = USB_OTG_FS;
  hpcd_USB_OTG_FS.Init.dev_endpoints = 4;
  hpcd_USB_OTG_FS.Init.speed = PCD_SPEED_FULL;
  hpcd_USB_OTG_FS.Init.dma_enable = DISABLE;
  hpcd_USB_OTG_FS.Init.phy_itface = PCD_PHY_EMBEDDED;
  hpcd_USB_OTG_FS.Init.Sof_enable = DISABLE;
  hpcd_USB_OTG_FS.Init.low_power_enable = DISABLE;
  hpcd_USB_OTG_FS.Init.lpm_enable = DISABLE;
  hpcd_USB_OTG_FS.Init.vbus_sensing_enable = ENABLE;
  hpcd_USB_OTG_FS.Init.use_dedicated_ep1 = DISABLE;
  if (HAL_PCD_Init(&hpcd_USB_OTG_FS) != HAL_OK)
  {
    Error_Handler();
  }

}

static void MX_DMA_Init(void)
{

  /* DMA controller clock enable */
  __HAL_RCC_DMA2_CLK_ENABLE();

  /* DMA interrupt init */
  /* DMA2_Stream1_IRQn interrupt configuration */
  HAL_NVIC_SetPriority(DMA2_Stream1_IRQn, 0, 0);
  HAL_NVIC_EnableIRQ(DMA2_Stream1_IRQn);

}

static void MX_GPIO_Init(void)
{
  GPIO_InitTypeDef GPIO_InitStruct = {0};

  /* GPIO Ports Clock Enable */
  __HAL_RCC_GPIOE_CLK_ENABLE();
  __HAL_RCC_GPIOC_CLK_ENABLE();
  __HAL_RCC_GPIOF_CLK_ENABLE();
  __HAL_RCC_GPIOH_CLK_ENABLE();
  __HAL_RCC_GPIOA_CLK_ENABLE();
  __HAL_RCC_GPIOB_CLK_ENABLE();
  __HAL_RCC_GPIOG_CLK_ENABLE();
  __HAL_RCC_GPIOD_CLK_ENABLE();

  /*Configure GPIO pin Output Level */
  HAL_GPIO_WritePin(GPIOE, DAC2_SBIT_Pin|DAC1_SBIT_Pin|DAC12_SH_Pin|LDIG3_Pin, GPIO_PIN_RESET);

  /*Configure GPIO pin Output Level */
  HAL_GPIO_WritePin(GPIOC, AI01_SH_Pin|FAN_EN_Pin|FAULT_W_Pin|LED1_Pin, GPIO_PIN_RESET);

  /*Configure GPIO pin Output Level */
  HAL_GPIO_WritePin(GPIOF, BREAK_RES_Pin|LDIG0_Pin, GPIO_PIN_RESET);

  /*Configure GPIO pin Output Level */
  HAL_GPIO_WritePin(ENCODER_VCC_EN_GPIO_Port, ENCODER_VCC_EN_Pin, GPIO_PIN_SET);

  /*Configure GPIO pin Output Level */
  HAL_GPIO_WritePin(GPIOG, LDIG1_Pin|LDIG2_Pin|FAULT_UVW_EN_AND_RESET_Pin|CHARGE_RELAY_Pin
                          |LED0_Pin|OUT1_Pin|OUT2_Pin|OUT3_Pin
                          |OUT4_Pin, GPIO_PIN_RESET);

  /*Configure GPIO pin Output Level */
  HAL_GPIO_WritePin(GPIOB, LDIG4_Pin|LDIG5_Pin|LDIG6_Pin|LDIG7_Pin
                          |LDIG0_SEL0_Pin|LDIG0_SEL1_Pin, GPIO_PIN_RESET);

  /*Configure GPIO pin Output Level */
  HAL_GPIO_WritePin(GPIOD, LDIG2_SEL_Pin|LDIG3_SEL_Pin|LDIG4_SEL_Pin|LDIG5_SEL_Pin
                          |ENDAT_CLK_EN_OR_WN_ENABLE_Pin|LED2_Pin|ENDAT_TX_EN_OR_USART2_RTS_Pin|OUT0_Pin, GPIO_PIN_RESET);

  /*Configure GPIO pins : AI0_SBIT_Pin AI1_SBIT_Pin PE14 DI6_Pin
                           DI7_Pin */
  GPIO_InitStruct.Pin = AI0_SBIT_Pin|AI1_SBIT_Pin|GPIO_PIN_14|DI6_Pin
                          |DI7_Pin;
  GPIO_InitStruct.Mode = GPIO_MODE_INPUT;
  GPIO_InitStruct.Pull = GPIO_NOPULL;
  HAL_GPIO_Init(GPIOE, &GPIO_InitStruct);

  /*Configure GPIO pins : DAC2_SBIT_Pin DAC1_SBIT_Pin DAC12_SH_Pin LDIG3_Pin */
  GPIO_InitStruct.Pin = DAC2_SBIT_Pin|DAC1_SBIT_Pin|DAC12_SH_Pin|LDIG3_Pin;
  GPIO_InitStruct.Mode = GPIO_MODE_OUTPUT_PP;
  GPIO_InitStruct.Pull = GPIO_NOPULL;
  GPIO_InitStruct.Speed = GPIO_SPEED_FREQ_LOW;
  HAL_GPIO_Init(GPIOE, &GPIO_InitStruct);

  /*Configure GPIO pins : AI01_SH_Pin FAN_EN_Pin FAULT_W_Pin LED1_Pin */
  GPIO_InitStruct.Pin = AI01_SH_Pin|FAN_EN_Pin|FAULT_W_Pin|LED1_Pin;
  GPIO_InitStruct.Mode = GPIO_MODE_OUTPUT_PP;
  GPIO_InitStruct.Pull = GPIO_NOPULL;
  GPIO_InitStruct.Speed = GPIO_SPEED_FREQ_LOW;
  HAL_GPIO_Init(GPIOC, &GPIO_InitStruct);

  /*Configure GPIO pins : I2C2_SDA_Pin I2C2_SCL_Pin */
  GPIO_InitStruct.Pin = I2C2_SDA_Pin|I2C2_SCL_Pin;
  GPIO_InitStruct.Mode = GPIO_MODE_AF_OD;
  GPIO_InitStruct.Pull = GPIO_PULLUP;
  GPIO_InitStruct.Speed = GPIO_SPEED_FREQ_VERY_HIGH;
  GPIO_InitStruct.Alternate = GPIO_AF4_I2C2;
  HAL_GPIO_Init(GPIOF, &GPIO_InitStruct);

  /*Configure GPIO pins : BREAK_RES_Pin LDIG0_Pin */
  GPIO_InitStruct.Pin = BREAK_RES_Pin|LDIG0_Pin;
  GPIO_InitStruct.Mode = GPIO_MODE_OUTPUT_PP;
  GPIO_InitStruct.Pull = GPIO_NOPULL;
  GPIO_InitStruct.Speed = GPIO_SPEED_FREQ_LOW;
  HAL_GPIO_Init(GPIOF, &GPIO_InitStruct);

  /*Configure GPIO pin : ENCODER_VCC_EN_Pin */
  GPIO_InitStruct.Pin = ENCODER_VCC_EN_Pin;
  GPIO_InitStruct.Mode = GPIO_MODE_OUTPUT_OD;
  GPIO_InitStruct.Pull = GPIO_NOPULL;
  GPIO_InitStruct.Speed = GPIO_SPEED_FREQ_LOW;
  HAL_GPIO_Init(ENCODER_VCC_EN_GPIO_Port, &GPIO_InitStruct);

  /*Configure GPIO pins : ENCODER_OC_Pin FAULT_IPM_Pin POWER_STAGE_EN_Pin FAULT_V_Pin
                           FAULT_U_Pin FAULT_RST_Pin */
  GPIO_InitStruct.Pin = ENCODER_OC_Pin|FAULT_IPM_Pin|POWER_STAGE_EN_Pin|FAULT_V_Pin
                          |FAULT_U_Pin|FAULT_RST_Pin;
  GPIO_InitStruct.Mode = GPIO_MODE_INPUT;
  GPIO_InitStruct.Pull = GPIO_NOPULL;
  HAL_GPIO_Init(GPIOF, &GPIO_InitStruct);

  /*Configure GPIO pins : BOOT1_Pin DI0_Pin DI1_Pin DI2_Pin
                           DI3_Pin DI4_Pin DI5_Pin */
  GPIO_InitStruct.Pin = BOOT1_Pin|DI0_Pin|DI1_Pin|DI2_Pin
                          |DI3_Pin|DI4_Pin|DI5_Pin;
  GPIO_InitStruct.Mode = GPIO_MODE_INPUT;
  GPIO_InitStruct.Pull = GPIO_NOPULL;
  HAL_GPIO_Init(GPIOB, &GPIO_InitStruct);

  /*Configure GPIO pins : LDIG1_Pin LDIG2_Pin FAULT_UVW_EN_AND_RESET_Pin CHARGE_RELAY_Pin
                           LED0_Pin OUT1_Pin OUT2_Pin OUT3_Pin
                           OUT4_Pin */
  GPIO_InitStruct.Pin = LDIG1_Pin|LDIG2_Pin|FAULT_UVW_EN_AND_RESET_Pin|CHARGE_RELAY_Pin
                          |LED0_Pin|OUT1_Pin|OUT2_Pin|OUT3_Pin
                          |OUT4_Pin;
  GPIO_InitStruct.Mode = GPIO_MODE_OUTPUT_PP;
  GPIO_InitStruct.Pull = GPIO_NOPULL;
  GPIO_InitStruct.Speed = GPIO_SPEED_FREQ_LOW;
  HAL_GPIO_Init(GPIOG, &GPIO_InitStruct);

  /*Configure GPIO pins : LDIG4_Pin LDIG5_Pin LDIG6_Pin LDIG7_Pin
                           LDIG0_SEL0_Pin LDIG0_SEL1_Pin */
  GPIO_InitStruct.Pin = LDIG4_Pin|LDIG5_Pin|LDIG6_Pin|LDIG7_Pin
                          |LDIG0_SEL0_Pin|LDIG0_SEL1_Pin;
  GPIO_InitStruct.Mode = GPIO_MODE_OUTPUT_PP;
  GPIO_InitStruct.Pull = GPIO_NOPULL;
  GPIO_InitStruct.Speed = GPIO_SPEED_FREQ_LOW;
  HAL_GPIO_Init(GPIOB, &GPIO_InitStruct);

  /*Configure GPIO pins : LDIG2_SEL_Pin LDIG3_SEL_Pin LDIG4_SEL_Pin LDIG5_SEL_Pin
                           ENDAT_CLK_EN_OR_WN_ENABLE_Pin LED2_Pin ENDAT_TX_EN_OR_USART2_RTS_Pin OUT0_Pin */
  GPIO_InitStruct.Pin = LDIG2_SEL_Pin|LDIG3_SEL_Pin|LDIG4_SEL_Pin|LDIG5_SEL_Pin
                          |ENDAT_CLK_EN_OR_WN_ENABLE_Pin|LED2_Pin|ENDAT_TX_EN_OR_USART2_RTS_Pin|OUT0_Pin;
  GPIO_InitStruct.Mode = GPIO_MODE_OUTPUT_PP;
  GPIO_InitStruct.Pull = GPIO_NOPULL;
  GPIO_InitStruct.Speed = GPIO_SPEED_FREQ_LOW;
  HAL_GPIO_Init(GPIOD, &GPIO_InitStruct);

  /*Configure GPIO pins : TIM4_CH1_Pin ENC_U_Pin ENC_V_Pin ENC_W_Pin */
  GPIO_InitStruct.Pin = TIM4_CH1_Pin|ENC_U_Pin|ENC_V_Pin|ENC_W_Pin;
  GPIO_InitStruct.Mode = GPIO_MODE_AF_PP;
  GPIO_InitStruct.Pull = GPIO_NOPULL;
  GPIO_InitStruct.Speed = GPIO_SPEED_FREQ_LOW;
  GPIO_InitStruct.Alternate = GPIO_AF2_TIM4;
  HAL_GPIO_Init(GPIOD, &GPIO_InitStruct);

  /*Configure GPIO pins : KEY2_Pin KEY3_Pin KEY4_Pin KEY5_Pin */
  GPIO_InitStruct.Pin = KEY2_Pin|KEY3_Pin|KEY4_Pin|KEY5_Pin;
  GPIO_InitStruct.Mode = GPIO_MODE_INPUT;
  GPIO_InitStruct.Pull = GPIO_NOPULL;
  HAL_GPIO_Init(GPIOG, &GPIO_InitStruct);

  /*Configure GPIO pins : PULSE_TIM8_CH1_Pin SIGN_TIM8_CH2_Pin */
  GPIO_InitStruct.Pin = PULSE_TIM8_CH1_Pin|SIGN_TIM8_CH2_Pin;
  GPIO_InitStruct.Mode = GPIO_MODE_AF_PP;
  GPIO_InitStruct.Pull = GPIO_NOPULL;
  GPIO_InitStruct.Speed = GPIO_SPEED_FREQ_LOW;
  GPIO_InitStruct.Alternate = GPIO_AF3_TIM8;
  HAL_GPIO_Init(GPIOC, &GPIO_InitStruct);

  /*Configure GPIO pin : USB_PU_RES_Pin */
  GPIO_InitStruct.Pin = USB_PU_RES_Pin;
  GPIO_InitStruct.Mode = GPIO_MODE_INPUT;
  GPIO_InitStruct.Pull = GPIO_NOPULL;
  HAL_GPIO_Init(USB_PU_RES_GPIO_Port, &GPIO_InitStruct);

  /*Configure GPIO pins : USART2_TX_Pin USART2_RX_Pin */
  GPIO_InitStruct.Pin = USART2_TX_Pin|USART2_RX_Pin;
  GPIO_InitStruct.Mode = GPIO_MODE_AF_PP;
  GPIO_InitStruct.Pull = GPIO_NOPULL;
  GPIO_InitStruct.Speed = GPIO_SPEED_FREQ_VERY_HIGH;
  GPIO_InitStruct.Alternate = GPIO_AF7_USART2;
  HAL_GPIO_Init(GPIOD, &GPIO_InitStruct);

  /*Configure GPIO pins : RS485_RX_USART6_RX_Pin RS485_DE_USART6_RTS_Pin RS485_TX_USART6_TX_Pin */
  GPIO_InitStruct.Pin = RS485_RX_USART6_RX_Pin|RS485_DE_USART6_RTS_Pin|RS485_TX_USART6_TX_Pin;
  GPIO_InitStruct.Mode = GPIO_MODE_AF_PP;
  GPIO_InitStruct.Pull = GPIO_NOPULL;
  GPIO_InitStruct.Speed = GPIO_SPEED_FREQ_VERY_HIGH;
  GPIO_InitStruct.Alternate = GPIO_AF8_USART6;
  HAL_GPIO_Init(GPIOG, &GPIO_InitStruct);

}

/* USER CODE BEGIN 4 */
void ADC_IRQHandler(void)
{
	/*HAL_ADC_IRQHandler(&hadc1);
	HAL_ADC_IRQHandler(&hadc2);
	HAL_ADC_IRQHandler(&hadc3);
	return;*/

	uint32_t tmp1 = 0U;//, tmp2 = 0U;

	GPIOC->BSRR |= LED1_Pin;

	tim3 = TIM3->CNT;
	tim5 = TIM5->CNT;

	tmp1 = __HAL_ADC_GET_FLAG( &hadc1, ADC_FLAG_EOC );
	//tmp2 = __HAL_ADC_GET_IT_SOURCE( &hadc1, ADC_IT_EOC );
	if( tmp1 )//&& tmp2 )
	{
		__HAL_ADC_CLEAR_FLAG( &hadc1, ADC_FLAG_STRT | ADC_FLAG_EOC );
	}

	tmp1 = __HAL_ADC_GET_FLAG( &hadc1, ADC_FLAG_JEOC );
	//tmp2 = __HAL_ADC_GET_IT_SOURCE( &hadc1, ADC_IT_JEOC );
	if( tmp1 )//&& tmp2 )
	{
		arrADC[0] = ADC1->JDR1;
		arrADC[1] = ADC1->JDR2;
		arrADC[2] = ADC1->JDR3;
		arrADC[3] = ADC1->JDR4;

		__HAL_ADC_CLEAR_FLAG( &hadc1, (ADC_FLAG_JSTRT | ADC_FLAG_JEOC) );
	}

	tmp1 = __HAL_ADC_GET_FLAG( &hadc2, ADC_FLAG_EOC );
	//tmp2 = __HAL_ADC_GET_IT_SOURCE( &hadc2, ADC_IT_EOC );
	if( tmp1 )//&& tmp2 )
	{
		__HAL_ADC_CLEAR_FLAG( &hadc2, ADC_FLAG_STRT | ADC_FLAG_EOC );
	}

	tmp1 = __HAL_ADC_GET_FLAG( &hadc2, ADC_FLAG_JEOC );
	//tmp2 = __HAL_ADC_GET_IT_SOURCE( &hadc2, ADC_IT_JEOC );
	if( tmp1 )//&& tmp2 )
	{
		arrADC[4] = ADC2->JDR1;
		arrADC[5] = ADC2->JDR2;
		arrADC[6] = ADC2->JDR3;
		arrADC[7] = ADC2->JDR4;

		__HAL_ADC_CLEAR_FLAG( &hadc2, (ADC_FLAG_JSTRT | ADC_FLAG_JEOC) );
	}

	tmp1 = __HAL_ADC_GET_FLAG( &hadc3, ADC_FLAG_EOC );
	//tmp2 = __HAL_ADC_GET_IT_SOURCE( &hadc3, ADC_IT_EOC );
	if( tmp1 )//&& tmp2 )
	{
		__HAL_ADC_CLEAR_FLAG( &hadc3, ADC_FLAG_STRT | ADC_FLAG_EOC );
	}

	tmp1 = __HAL_ADC_GET_FLAG( &hadc3, ADC_FLAG_JEOC );
	//tmp2 = __HAL_ADC_GET_IT_SOURCE( &hadc3, ADC_IT_JEOC );
	if( tmp1 ) //&& tmp2 )
	{
		arrADC[8] = ADC3->JDR1;
		arrADC[9] = ADC3->JDR2;
		arrADC[10] = ADC3->JDR3;
		arrADC[11] = ADC3->JDR4;

		__HAL_ADC_CLEAR_FLAG( &hadc3, (ADC_FLAG_JSTRT | ADC_FLAG_JEOC) );
	}

	adc_is_ready = 1;

	stFoc.current_a = arrADC[0];
	stFoc.current_b = arrADC[4];
	stFoc.current_c = arrADC[8];
	adc_current_filter( (uint16_t*)&stFoc.current_a, (uint16_t*)&stFoc.current_b, (uint16_t*)&stFoc.current_c, 2 );

	if( 4 == main_state )
	{
		extern volatile uint64_t post;

		mcFocSetAngle( &stFoc, post % ROTOR_ENCODER_PERIOD );
		mcRunFoc( &stFoc );
	}

	GPIOC->BSRR |= LED1_Pin<<16;
}

void main_callback(void)
{
	static float sum = 0.0f, old = 0.0f;
	static int c = 0;

	if( c < 4 )
	{
		sum += ( angle - old );
		c++;
	} else {
		delta = sum / 4.0f;
		sum = 0;
		c = 0;
	}

	old = angle;
}

float arr_sin[ ROTOR_ENCODER_PERIOD + 1 ], arr_cos[ ROTOR_ENCODER_PERIOD + 1 ];

void createSinCosTable(void)
{
	for( int i = 0; i <= ROTOR_ENCODER_PERIOD; i++ ) {
		arr_sin[i] = sinf( deg_to_rad( (float)i * ( 360.0f / (float)ROTOR_ENCODER_PERIOD ) ) );
		arr_cos[i] = cosf( deg_to_rad( (float)i * ( 360.0f / (float)ROTOR_ENCODER_PERIOD ) ) );
	}
}

float fSinAngle(int angle)
{
	return arr_sin[angle];
}

float fCosAngle(int angle)
{
	return arr_cos[angle];
}

/* USER CODE END 4 */

void Error_Handler(void)
{
}

/************************ (C) COPYRIGHT STMicroelectronics *****END OF FILE****/
